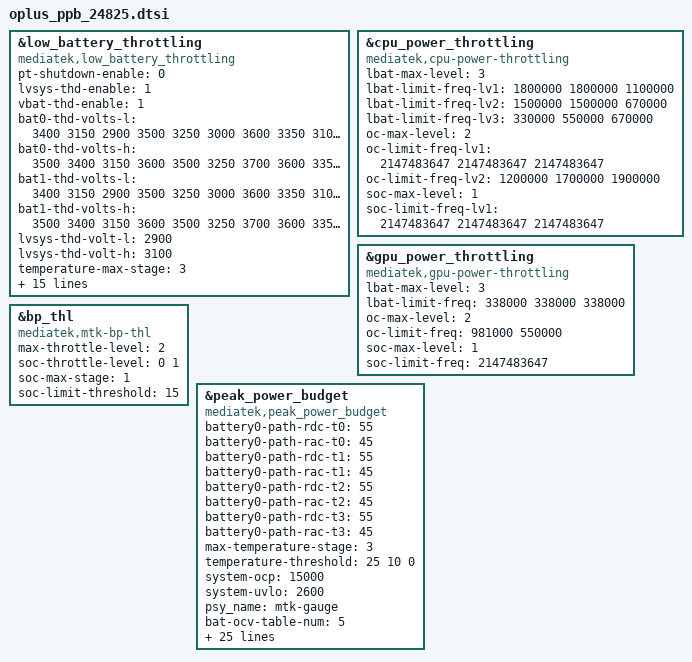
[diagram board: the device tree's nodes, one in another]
// SPDX-License-Identifier: GPL-2.0-only
/*
* Copyright (C) 2024-2025 Oplus. All rights reserved.
*/
#include <dt-bindings/iio/mt635x-auxadc.h>
#include <dt-bindings/pinctrl/mt6989-pinfunc.h>

&low_battery_throttling {
		compatible = "mediatek,low_battery_throttling";
		pt-shutdown-enable = <0>;
		lvsys-thd-enable = <1>;
		vbat-thd-enable = <1>;
		bat0-thd-volts-l = <
			3400 3150 2900
			3500 3250 3000
			3600 3350 3100
			3750 3500 3250>;
		bat0-thd-volts-h = <
			3500 3400 3150
			3600 3500 3250
			3700 3600 3350
			3850 3750 3500>;
		bat1-thd-volts-l = <
			3400 3150 2900
			3500 3250 3000
			3600 3350 3100
			3750 3500 3250>;
		bat1-thd-volts-h = <
			3500 3400 3150
			3600 3500 3250
			3700 3600 3350
			3850 3750 3500>;
		lvsys-thd-volt-l = <2900>;
		lvsys-thd-volt-h = <3100>;
		temperature-max-stage = <3>;
		temperature-stage-threshold = <25 10 0>;

		bat0-aging-threshold = <1000 2000>;
		bat0-aging-volts-t0 =  <0 0>;
		bat0-aging-volts-t1 =  <0 0>;
		bat0-aging-volts-t2 =  <0 0>;
		bat0-aging-volts-t3 =  <0 0>;
		bat1-aging-threshold = <1000 2000>;
		bat1-aging-volts-t0 =  <0 0>;
		bat1-aging-volts-t1 =  <0 0>;
		bat1-aging-volts-t2 =  <0 0>;
		bat1-aging-volts-t3 =  <0 0>;

		throttle-level = <0 1 2 3>,
						<0 1 2 3>,
						<0 1 2 3>,
						<0 1 2 3>;
		bootmode = <&chosen>;
		gauge = <&mtk_gauge>;
	};

&cpu_power_throttling {
		compatible = "mediatek,cpu-power-throttling";

		lbat-max-level = <3>;
		lbat-limit-freq-lv1 = < 1800000  1800000 1100000>;
		lbat-limit-freq-lv2 = < 1500000  1500000 670000>;
		lbat-limit-freq-lv3 = < 330000   550000 670000>;

		oc-max-level = <2>;
		oc-limit-freq-lv1 = < 2147483647  2147483647 2147483647>;
		oc-limit-freq-lv2 = < 1200000  1700000 1900000>;

		soc-max-level = <1>;
		soc-limit-freq-lv1 = < 2147483647  2147483647 2147483647>;
	};

&gpu_power_throttling {
		compatible = "mediatek,gpu-power-throttling";

		lbat-max-level = <3>;
		lbat-limit-freq = <338000 338000 338000>;

		oc-max-level = <2>;
		oc-limit-freq = <981000 550000>;

		soc-max-level = <1>;
		soc-limit-freq = <2147483647>;
	};

	&bp_thl {
		compatible = "mediatek,mtk-bp-thl";

		max-throttle-level = <2>;
		soc-throttle-level = < 0 1>;

		soc-max-stage = <1>;
		soc-limit-threshold = <15>;
	};

/* config for the power budget (PPB), which need to review by performance module. */
&peak_power_budget {
	compatible = "mediatek,peak_power_budget";
	battery0-path-rdc-t0 = <55>;
	battery0-path-rac-t0 = <45>;
	battery0-path-rdc-t1 = <55>;
	battery0-path-rac-t1 = <45>;
	battery0-path-rdc-t2 = <55>;
	battery0-path-rac-t2 = <45>;
	battery0-path-rdc-t3 = <55>;
	battery0-path-rac-t3 = <45>;
	max-temperature-stage = <3>;
	temperature-threshold = <25 10 0>;
	system-ocp = <15000>;
	system-uvlo = <2600>;

	/* use the mtk plateform gauge: mtk-gauge */
	psy_name = "mtk-gauge";
	bat-ocv-table-num = <5>;  /* The table number of the following tables: t0 ~ t4 */

	bat0-ocv-table-t0-temperature = <50>;
	bat0-ocv-table-t0-qmax = <6845>;
	bat0-ocv-table-t0-size = <100>;
	bat0-ocv-table-t0 = <
		0       44549  0  631
		704     44334  0  634
		1407    44168  0  634
		2111    44027  0  641
		2815    43898  0  646
		3519    43778  0  646
		4222    43665  0  650
		4926    43552  0  644
		5630    43438  0  644
		6334    43324  0  640
		7037    43212  0  646
		7741    43097  0  651
		8445    42980  0  649
		9149    42858  0  654
		9852    42732  0  656
		10556   42613  0  658
		11260   42489  0  649
		11963   42363  0  653
		12667   42238  0  657
		13371   42112  0  656
		14075   41987  0  651
		14778   41862  0  650
		15482   41745  0  659
		16186   41622  0  658
		16890   41502  0  664
		17593   41383  0  655
		18297   41263  0  653
		19001   41152  0  664
		19704   41037  0  664
		20408   40924  0  652
		21112   40817  0  672
		21816   40707  0  669
		22519   40603  0  680
		23223   40494  0  667
		23927   40395  0  687
		24631   40291  0  694
		25334   40194  0  695
		26038   40096  0  698
		26742   39998  0  701
		27446   39907  0  705
		28149   39815  0  710
		28853   39723  0  735
		29557   39638  0  748
		30260   39526  0  749
		30964   39365  0  693
		31668   39212  0  677
		32372   39098  0  670
		33075   39011  0  663
		33779   38935  0  665
		34483   38863  0  665
		35187   38792  0  657
		35890   38734  0  680
		36594   38675  0  663
		37298   38609  0  662
		38001   38557  0  663
		38705   38499  0  657
		39409   38451  0  661
		40113   38403  0  675
		40816   38356  0  671
		41520   38309  0  680
		42224   38266  0  688
		42928   38223  0  667
		43631   38179  0  675
		44335   38142  0  679
		45039   38105  0  681
		45743   38068  0  692
		46446   38027  0  682
		47150   37995  0  694
		47854   37963  0  696
		48557   37924  0  697
		49261   37853  0  670
		49965   37764  0  660
		50669   37682  0  664
		51372   37628  0  664
		52076   37574  0  659
		52780   37522  0  669
		53484   37470  0  663
		54187   37416  0  661
		54891   37376  0  674
		55595   37337  0  669
		56298   37296  0  688
		57002   37237  0  677
		57706   37172  0  678
		58410   37097  0  662
		59113   37036  0  664
		59817   36959  0  678
		60521   36876  0  663
		61225   36834  0  653
		61928   36816  0  651
		62632   36806  0  678
		63336   36791  0  694
		64040   36764  0  710
		64743   36705  0  721
		65447   36480  0  680
		66151   36036  0  713
		66854   35450  0  731
		67558   34663  0  779
		68262   33490  0  905
		68966   31294  0  3903
		69669   30760  0  5264
	>;

	bat0-ocv-table-t1-temperature = <25>;
	bat0-ocv-table-t1-qmax = <6937>;
	bat0-ocv-table-t1-size = <100>;
	bat0-ocv-table-t1 = <
		0       44611  0   960
		704     44401  0   948
		1407    44238  0   929
		2111    44106  0   922
		2815    43983  0   914
		3519    43862  0   884
		4222    43753  0   901
		4926    43648  0   910
		5630    43535  0   898
		6334    43419  0   883
		7037    43310  0   897
		7741    43193  0   893
		8445    43079  0   912
		9149    42954  0   882
		9852    42834  0   898
		10556   42712  0   908
		11260   42588  0   900
		11963   42468  0   914
		12667   42336  0   893
		13371   42213  0   897
		14075   42084  0   883
		14778   41964  0   899
		15482   41844  0   908
		16186   41724  0   907
		16890   41599  0   887
		17593   41479  0   885
		18297   41365  0   905
		19001   41251  0   915
		19704   41138  0   915
		20408   41017  0   897
		21112   40910  0   919
		21816   40805  0   929
		22519   40696  0   933
		23223   40587  0   929
		23927   40489  0   958
		24631   40382  0   955
		25334   40285  0   973
		26038   40188  0   988
		26742   40090  0   977
		27446   39995  0   989
		28149   39903  0   1008
		28853   39809  0   993
		29557   39722  0   1035
		30260   39622  0   1036
		30964   39511  0   1027
		31668   39353  0   962
		32372   39206  0   906
		33075   39094  0   892
		33779   38997  0   868
		34483   38921  0   882
		35187   38850  0   855
		35890   38785  0   864
		36594   38719  0   853
		37298   38666  0   867
		38001   38601  0   854
		38705   38550  0   853
		39409   38500  0   865
		40113   38449  0   865
		40816   38401  0   869
		41520   38353  0   867
		42224   38310  0   877
		42928   38264  0   868
		43631   38232  0   883
		44335   38197  0   891
		45039   38154  0   868
		45743   38119  0   878
		46446   38076  0   854
		47150   38047  0   905
		47854   38011  0   900
		48557   37980  0   888
		49261   37946  0   870
		49965   37917  0   869
		50669   37879  0   905
		51372   37820  0   870
		52076   37770  0   854
		52780   37727  0   842
		53484   37688  0   871
		54187   37637  0   848
		54891   37591  0   841
		55595   37558  0   868
		56298   37507  0   832
		57002   37472  0   853
		57706   37419  0   864
		58410   37348  0   850
		59113   37287  0   857
		59817   37221  0   838
		60521   37158  0   855
		61225   37064  0   841
		61928   37009  0   841
		62632   36992  0   853
		63336   36978  0   858
		64040   36961  0   883
		64743   36935  0   883
		65447   36893  0   898
		66151   36770  0   834
		66854   36433  0   898
		67558   35878  0   941
		68262   35126  0   985
		68966   34020  0   1104
		69669   31963  0   2095
	>;

	bat0-ocv-table-t2-temperature = <10>;
	bat0-ocv-table-t2-qmax = <6946>;
	bat0-ocv-table-t2-size = <100>;
	bat0-ocv-table-t2 = <
		0       44562  0   1250
		704     44340  0   1251
		1407    44196  0   1260
		2111    44073  0   1248
		2815    43960  0   1218
		3519    43858  0   1235
		4222    43749  0   1209
		4926    43647  0   1214
		5630    43544  0   1203
		6334    43435  0   1209
		7037    43323  0   1201
		7741    43216  0   1214
		8445    43096  0   1189
		9149    42982  0   1185
		9852    42861  0   1188
		10556   42743  0   1198
		11260   42624  0   1200
		11963   42499  0   1201
		12667   42373  0   1195
		13371   42248  0   1190
		14075   42122  0   1184
		14778   42003  0   1202
		15482   41879  0   1200
		16186   41762  0   1213
		16890   41637  0   1198
		17593   41517  0   1212
		18297   41399  0   1214
		19001   41281  0   1204
		19704   41166  0   1217
		20408   41053  0   1220
		21112   40943  0   1232
		21816   40834  0   1237
		22519   40726  0   1205
		23223   40617  0   1236
		23927   40511  0   1220
		24631   40410  0   1257
		25334   40310  0   1270
		26038   40218  0   1300
		26742   40118  0   1312
		27446   40019  0   1304
		28149   39931  0   1338
		28853   39833  0   1361
		29557   39730  0   1350
		30260   39622  0   1356
		30964   39494  0   1334
		31668   39342  0   1257
		32372   39200  0   1182
		33075   39083  0   1163
		33779   38989  0   1130
		34483   38908  0   1128
		35187   38835  0   1117
		35890   38764  0   1120
		36594   38699  0   1108
		37298   38639  0   1121
		38001   38584  0   1113
		38705   38526  0   1133
		39409   38470  0   1128
		40113   38421  0   1129
		40816   38373  0   1145
		41520   38321  0   1140
		42224   38278  0   1142
		42928   38234  0   1154
		43631   38190  0   1154
		44335   38153  0   1164
		45039   38116  0   1185
		45743   38072  0   1169
		46446   38039  0   1173
		47150   38006  0   1172
		47854   37980  0   1202
		48557   37947  0   1203
		49261   37913  0   1196
		49965   37885  0   1202
		50669   37855  0   1207
		51372   37829  0   1220
		52076   37792  0   1208
		52780   37748  0   1182
		53484   37705  0   1174
		54187   37662  0   1195
		54891   37606  0   1173
		55595   37565  0   1171
		56298   37533  0   1202
		57002   37487  0   1188
		57706   37444  0   1196
		58410   37385  0   1211
		59113   37313  0   1193
		59817   37251  0   1215
		60521   37186  0   1207
		61225   37115  0   1236
		61928   37019  0   1222
		62632   36966  0   1238
		63336   36944  0   1251
		64040   36916  0   1247
		64743   36889  0   1267
		65447   36855  0   1295
		66151   36796  0   1339
		66854   36645  0   1403
		67558   36253  0   1513
		68262   35655  0   1763
		68966   34803  0   2694
		69669   33978  0   5782
	>;

	bat0-ocv-table-t3-temperature = <0>;
	bat0-ocv-table-t3-qmax = <6683>;
	bat0-ocv-table-t3-size = <100>;
	bat0-ocv-table-t3 = <
		0       44624  0   2201
		704     44374  0   2196
		1407    44206  0   2177
		2111    44072  0   2151
		2815    43952  0   2128
		3519    43845  0   2114
		4222    43737  0   2094
		4926    43630  0   2079
		5630    43522  0   2066
		6334    43413  0   2047
		7037    43304  0   2044
		7741    43190  0   2024
		8445    43073  0   2013
		9149    42953  0   1998
		9852    42836  0   1983
		10556   42712  0   1977
		11260   42589  0   1973
		11963   42465  0   1962
		12667   42341  0   1952
		13371   42217  0   1945
		14075   42091  0   1943
		14778   41966  0   1937
		15482   41843  0   1926
		16186   41723  0   1929
		16890   41603  0   1929
		17593   41483  0   1929
		18297   41363  0   1924
		19001   41246  0   1925
		19704   41133  0   1937
		20408   41018  0   1944
		21112   40906  0   1944
		21816   40794  0   1948
		22519   40685  0   1961
		23223   40579  0   1967
		23927   40473  0   1972
		24631   40370  0   1986
		25334   40269  0   2001
		26038   40166  0   2008
		26742   40068  0   2023
		27446   39968  0   2039
		28149   39867  0   2042
		28853   39760  0   2040
		29557   39651  0   2040
		30260   39528  0   1997
		30964   39396  0   1947
		31668   39264  0   1880
		32372   39143  0   1829
		33075   39038  0   1804
		33779   38947  0   1786
		34483   38866  0   1772
		35187   38792  0   1766
		35890   38724  0   1769
		36594   38660  0   1771
		37298   38599  0   1774
		38001   38539  0   1774
		38705   38485  0   1782
		39409   38432  0   1789
		40113   38381  0   1795
		40816   38337  0   1445
		41520   38287  0   1808
		42224   38240  0   1812
		42928   38196  0   1827
		43631   38156  0   1837
		44335   38115  0   1844
		45039   38080  0   1863
		45743   38045  0   1880
		46446   38010  0   1882
		47150   37980  0   1905
		47854   37946  0   1902
		48557   37919  0   1924
		49261   37891  0   1936
		49965   37864  0   1942
		50669   37840  0   1960
		51372   37818  0   1941
		52076   37789  0   1976
		52780   37759  0   1976
		53484   37722  0   1982
		54187   37681  0   1935
		54891   37632  0   1985
		55595   37591  0   1996
		56298   37549  0   2014
		57002   37503  0   2040
		57706   37446  0   2066
		58410   37377  0   2098
		59113   37304  0   2132
		59817   37239  0   2175
		60521   37166  0   2231
		61225   37073  0   2293
		61928   36977  0   2376
		62632   36916  0   2503
		63336   36870  0   2695
		64040   36808  0   2973
		64743   36765  0   3426
		65447   36675  0   4757
		66151   36529  0   9044
		66854   36256  0   11144
		67558   36156  0   12144
		68262   36056  0   15144
		68966   35956  0   18144
		69669   35856  0   19144
	>;

	bat-ocv-table-t4-temperature = <(-10)>;
	bat-ocv-table-t4-qmax = <6418>;
	bat-ocv-table-t4-size = <100>;
	bat-ocv-table-t4 = <
		0       44766  0   4501
		704     44414  0   4457
		1407    44203  0   4508
		2111    44044  0   4388
		2815    43913  0   4396
		3519    43798  0   4374
		4222    43688  0   4427
		4926    43576  0   4448
		5630    43469  0   4306
		6334    43353  0   4291
		7037    43240  0   4272
		7741    43126  0   4254
		8445    43012  0   4334
		9149    42892  0   4210
		9852    42769  0   4175
		10556   42645  0   4158
		11260   42524  0   4210
		11963   42398  0   4087
		12667   42272  0   4086
		13371   42147  0   4059
		14075   42028  0   4076
		14778   41903  0   4198
		15482   41782  0   4012
		16186   41659  0   4007
		16890   41540  0   4075
		17593   41415  0   4124
		18297   41295  0   3961
		19001   41179  0   3997
		19704   41057  0   4034
		20408   40941  0   3992
		21112   40826  0   3992
		21816   40717  0   4001
		22519   40601  0   4042
		23223   40486  0   3983
		23927   40375  0   3991
		24631   40261  0   4003
		25334   40156  0   4077
		26038   40043  0   3983
		26742   39931  0   3981
		27446   39817  0   3977
		28149   39707  0   3922
		28853   39583  0   3895
		29557   39462  0   3887
		30260   39342  0   3826
		30964   39228  0   3804
		31668   39116  0   3813
		32372   39015  0   3743
		33075   38921  0   3744
		33779   38838  0   3750
		34483   38755  0   3774
		35187   38679  0   3734
		35890   38608  0   3739
		36594   38548  0   3766
		37298   38487  0   3793
		38001   38426  0   3726
		38705   38366  0   3746
		39409   38317  0   3731
		40113   38268  0   3883
		40816   38216  0   3837
		41520   38172  0   3880
		42224   38128  0   4014
		42928   38080  0   3892
		43631   38041  0   3938
		44335   38004  0   3988
		45039   37966  0   4127
		45743   37930  0   4052
		46446   37900  0   4094
		47150   37873  0   4162
		47854   37847  0   4384
		48557   37824  0   4231
		49261   37799  0   4274
		49965   37775  0   4385
		50669   37753  0   4390
		51372   37731  0   4425
		52076   37703  0   4502
		52780   37670  0   4634
		53484   37632  0   4608
		54187   37595  0   4740
		54891   37551  0   4858
		55595   37501  0   4937
		56298   37449  0   5071
		57002   37389  0   5232
		57706   37317  0   5489
		58410   37242  0   5715
		59113   37167  0   6018
		59817   37088  0   6576
		60521   36996  0   7134
		61225   36891  0   7812
		61928   36801  0   9166
		62632   36727  0   10929
		63336   36661  0   14682
		64040   36596  0   21984
		64743   36582  0   23948
		65447   36482  0   24048
		66151   36382  0   24148
		66854   36282  0   24248
		67558   36182  0   24348
		68262   36082  0   24448
		68966   35982  0   24548
		69669   35882  0   24648
	>;
};
